# ESP32-H21 register map
Vendor: ESPRESSIF SYSTEMS (SHANGHAI) CO., LTD.; Series: ESP32 H-Series; File version: 1
CPU: RV32IMAC r0p0, little endian, no MPU, no FPU, 0 interrupt priority bits
Address unit: 32 bits
Registers are 32-bit, read-write, reset 0x0 unless marked. A register's access mark holds for its fields unless they carry their own. Offsets are from the block's base; [hi:lo] are bit positions; {n}, {i} and the like mark numbered series.

## LEDC — LED Control PWM (Pulse Width Modulation)
Base 0x60008000
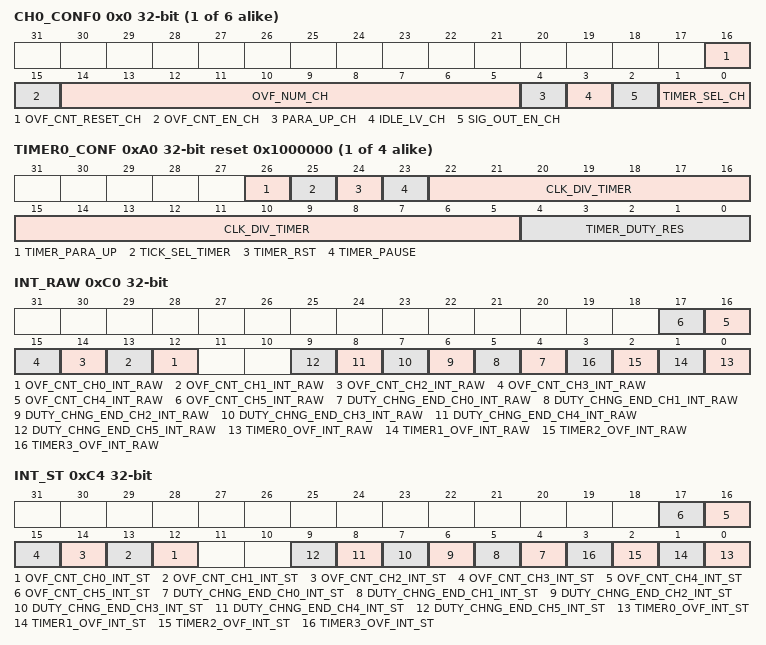
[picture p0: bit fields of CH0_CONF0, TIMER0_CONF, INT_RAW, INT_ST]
{0x0+0x14*i} CH{i}_CONF0 (i=0..5) access per field — Configuration register 0 for channel {i}
  [16] OVF_CNT_RESET_CH wo — Set this bit to reset the ovf_cnt of channel %s.
  [15] OVF_CNT_EN_CH rw — This bit is used to enable the ovf_cnt of channel %s.
  [14:5] OVF_NUM_CH rw — This register is used to configure the maximum times of overflow minus 1. The LEDC_OVF_CNT_CH%s_INT interrupt will be triggered when channel %s overflows for (LEDC_OVF_NUM_CH%s + 1) times.
  [4] PARA_UP_CH wo — This bit is used to update LEDC_HPOINT_CH%s, LEDC_DUTY_START_CH%s, LEDC_SIG_OUT_EN_CH%s, LEDC_TIMER_SEL_CH%s, LEDC_DUTY_NUM_CH%s, LEDC_DUTY_CYCLE_CH%s, LEDC_DUTY_SCALE_CH%s, LEDC_DUTY_INC_CH%s, and LEDC_OVF_CNT_EN_CH%s fields for channel %s, and will be automatically cleared by hardware.
  [3] IDLE_LV_CH rw — This bit is used to control the output value when channel %s is inactive (when LEDC_SIG_OUT_EN_CH%s is 0).
  [2] SIG_OUT_EN_CH rw — Set this bit to enable signal output on channel %s.
  [1:0] TIMER_SEL_CH rw — This field is used to select one of timers for channel %s. 0: select timer0, 1: select timer1, 2: select timer2, 3: select timer3
{0x4+0x14*i} CH{i}_HPOINT (i=0..5) — High point register for channel {i}
  [19:0] HPOINT_CH — The output value changes to high when the selected timers has reached the value specified by this register.
{0x8+0x14*i} CH{i}_DUTY (i=0..5) — Initial duty cycle for channel {i}
  [24:0] DUTY_CH — This register is used to change the output duty by controlling the Lpoint. The output value turns to low when the selected timers has reached the Lpoint.
{0xC+0x14*i} CH{i}_CONF1 (i=0..5) — Configuration register 1 for channel {i}
  [31] DUTY_START_CH — Other configured fields in LEDC_CH%s_CONF1_REG will start to take effect when this bit is set to 1.
{0x10+0x14*i} CH{i}_DUTY_R ro (i=0..2) — Current duty cycle for channel $n
  [24:0] DUTY_CH{i}_R — This register stores the current duty of output signal on channel {i}.
0x4C CH3_DUTY_R ro — Initial duty cycle for channel $n
  [24:0] DUTY_CH3_R — This register stores the current duty of output signal on channel 3.
0x60 CH4_DUTY_R ro — Current duty cycle for channel $n
  [24:0] DUTY_CH4_R — This register stores the current duty of output signal on channel 4.
0x74 CH5_DUTY_R ro — Current duty cycle for channel $n
  [24:0] DUTY_CH5_R — This register stores the current duty of output signal on channel 5.
{0xA0+8i} TIMER{i}_CONF (i=0..3) access per field reset 0x1000000 — Timer {i} configuration
  [26] TIMER_PARA_UP wo — Set this bit to update LEDC_CLK_DIV_TIMER%s and LEDC_TIMER%s_DUTY_RES.
  [25] TICK_SEL_TIMER rw — This bit is used to select clock for timer %s. When this bit is set to 1 LEDC_APB_CLK_SEL[1:0] should be 1, otherwise the timer clock may be not accurate. 1'h0: SLOW_CLK 1'h1: REF_TICK
  [24] TIMER_RST rw — This bit is used to reset timer %s. The counter will show 0 after reset.
  [23] TIMER_PAUSE rw — This bit is used to suspend the counter in timer %s.
  [22:5] CLK_DIV_TIMER rw — This register is used to configure the divisor for the divider in timer %s. The least significant eight bits represent the fractional part.
  [4:0] TIMER_DUTY_RES rw — This register is used to control the range of the counter in timer %s.
{0xA4+8i} TIMER{i}_VALUE (i=0..3) ro — Timer {i} current counter value
  [19:0] TIMER_CNT — This register stores the current counter value of timer %s.
0xC0 INT_RAW — Raw interrupt status
  [n+12] OVF_CNT_CH{n}_INT_RAW (n=0..5) — Interrupt raw bit for channel {n}. Triggered when the ovf_cnt has reached the value specified by LEDC_OVF_NUM_CH{n}.
  [n+4] DUTY_CHNG_END_CH{n}_INT_RAW (n=0..5) — Interrupt raw bit for channel {n}. Triggered when the gradual change of duty has finished.
  [n] TIMER{n}_OVF_INT_RAW (n=0..3) — Triggered when the timer{n} has reached its maximum counter value.
0xC4 INT_ST ro — Masked interrupt status
  [n+12] OVF_CNT_CH{n}_INT_ST (n=0..5) — This is the masked interrupt status bit for the LEDC_OVF_CNT_CH{n}_INT interrupt when LEDC_OVF_CNT_CH{n}_INT_ENA is set to 1.
  [n+4] DUTY_CHNG_END_CH{n}_INT_ST (n=0..5) — This is the masked interrupt status bit for the LEDC_DUTY_CHNG_END_CH{n}_INT interrupt when LEDC_DUTY_CHNG_END_CH{n}_INT_ENA is set to 1.
  [n] TIMER{n}_OVF_INT_ST (n=0..3) — This is the masked interrupt status bit for the LEDC_TIMER{n}_OVF_INT interrupt when LEDC_TIMER{n}_OVF_INT_ENA is set to 1.
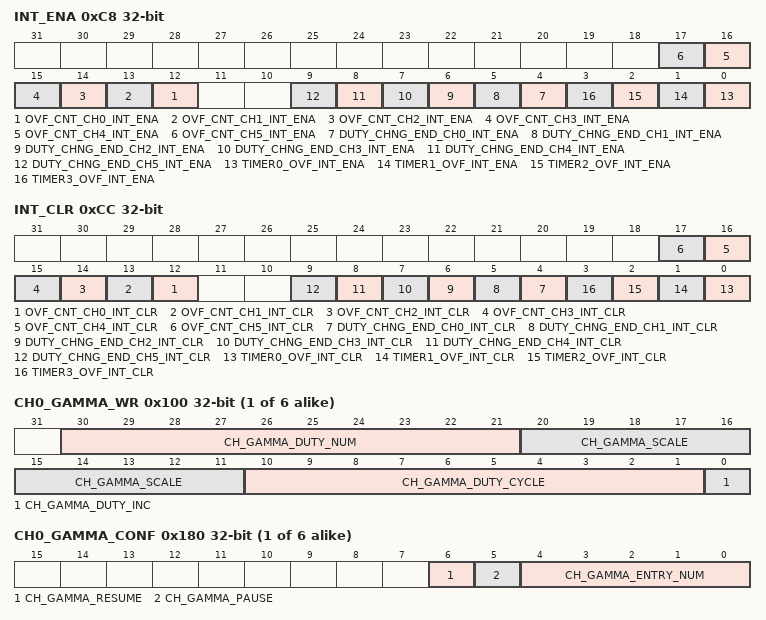
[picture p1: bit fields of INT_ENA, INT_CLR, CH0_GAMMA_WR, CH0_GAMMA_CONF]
0xC8 INT_ENA — Interrupt enable bits
  [n+12] OVF_CNT_CH{n}_INT_ENA (n=0..5) — The interrupt enable bit for the LEDC_OVF_CNT_CH{n}_INT interrupt.
  [n+4] DUTY_CHNG_END_CH{n}_INT_ENA (n=0..5) — The interrupt enable bit for the LEDC_DUTY_CHNG_END_CH{n}_INT interrupt.
  [n] TIMER{n}_OVF_INT_ENA (n=0..3) — The interrupt enable bit for the LEDC_TIMER{n}_OVF_INT interrupt.
0xCC INT_CLR wo — Interrupt clear bits
  [n+12] OVF_CNT_CH{n}_INT_CLR (n=0..5) — Set this bit to clear the LEDC_OVF_CNT_CH{n}_INT interrupt.
  [n+4] DUTY_CHNG_END_CH{n}_INT_CLR (n=0..5) — Set this bit to clear the LEDC_DUTY_CHNG_END_CH{n}_INT interrupt.
  [n] TIMER{n}_OVF_INT_CLR (n=0..3) — Set this bit to clear the LEDC_TIMER{n}_OVF_INT interrupt.
{0x100+0x10*i} CH{i}_GAMMA_WR (i=0..5) — Ledc ch{i} gamma ram write register.
  [30:21] CH_GAMMA_DUTY_NUM — Ledc ch%s gamma duty num of current ram write address.This register is used to control the number of times the duty cycle will be changed.
  [20:11] CH_GAMMA_SCALE — Ledc ch%s gamma scale of current ram write address.This register is used to configure the changing step scale of duty on channel %s.
  [10:1] CH_GAMMA_DUTY_CYCLE — Ledc ch%s gamma duty cycle of current ram write address.The duty will change every LEDC_CH%s_GAMMA_DUTY_CYCLE on channel %s.
  [0] CH_GAMMA_DUTY_INC — Ledc ch%s gamma duty inc of current ram write address.This register is used to increase or decrease the duty of output signal on channel %s. 1: Increase 0: Decrease.
{0x104+0x10*i} CH{i}_GAMMA_WR_ADDR (i=0..5) — Ledc ch{i} gamma ram write address register.
  [3:0] CH_GAMMA_WR_ADDR — Ledc ch%s gamma ram write address.
{0x108+0x10*i} CH{i}_GAMMA_RD_ADDR (i=0..5) — Ledc ch{i} gamma ram read address register.
  [3:0] CH_GAMMA_RD_ADDR — Ledc ch%s gamma ram read address.
{0x10C+0x10*i} CH{i}_GAMMA_RD_DATA (i=0..5) ro — Ledc ch{i} gamma ram read data register.
  [30:0] CH_GAMMA_RD_DATA — Ledc ch%s gamma ram read data.
{0x180+4i} CH{i}_GAMMA_CONF (i=0..5) access per field — Ledc ch{i} gamma config register.
  [6] CH_GAMMA_RESUME wo — Ledc ch%s gamma resume, write 1 to resume.
  [5] CH_GAMMA_PAUSE wo — Ledc ch%s gamma pause, write 1 to pause.
  [4:0] CH_GAMMA_ENTRY_NUM rw — Ledc ch%s gamma entry num.
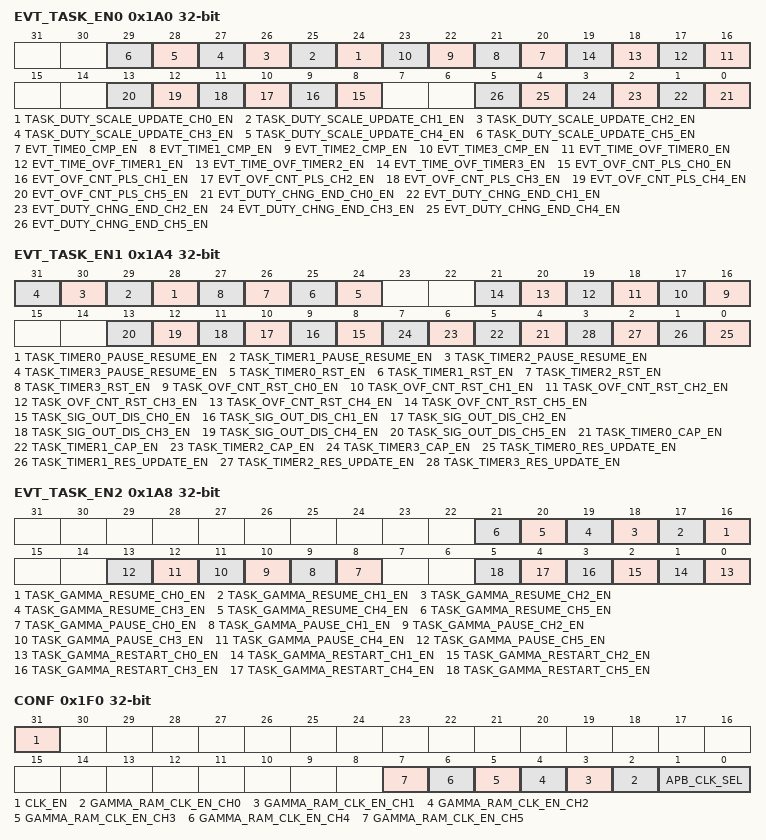
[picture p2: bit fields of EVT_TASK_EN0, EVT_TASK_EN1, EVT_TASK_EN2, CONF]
0x1A0 EVT_TASK_EN0 — Ledc event task enable bit register0.
  [n+24] TASK_DUTY_SCALE_UPDATE_CH{n}_EN (n=0..5) — Ledc ch{n} duty scale update task enable register, write 1 to enable this task.
  [n+20] EVT_TIME{n}_CMP_EN (n=0..3) — Ledc timer{n} compare event enable register, write 1 to enable this event.
  [n+16] EVT_TIME_OVF_TIMER{n}_EN (n=0..3) — Ledc timer{n} overflow event enable register, write 1 to enable this event.
  [n+8] EVT_OVF_CNT_PLS_CH{n}_EN (n=0..5) — Ledc ch{n} overflow count pulse event enable register, write 1 to enable this event.
  [n] EVT_DUTY_CHNG_END_CH{n}_EN (n=0..5) — Ledc ch{n} duty change end event enable register, write 1 to enable this event.
0x1A4 EVT_TASK_EN1 — Ledc event task enable bit register1.
  [n+28] TASK_TIMER{n}_PAUSE_RESUME_EN (n=0..3) — Ledc timer{n} pause resume task enable register, write 1 to enable this task.
  [n+24] TASK_TIMER{n}_RST_EN (n=0..3) — Ledc timer{n} reset task enable register, write 1 to enable this task.
  [n+16] TASK_OVF_CNT_RST_CH{n}_EN (n=0..5) — Ledc ch{n} overflow count reset task enable register, write 1 to enable this task.
  [n+8] TASK_SIG_OUT_DIS_CH{n}_EN (n=0..5) — Ledc ch{n} signal out disable task enable register, write 1 to enable this task.
  [n+4] TASK_TIMER{n}_CAP_EN (n=0..3) — Ledc timer{n} capture task enable register, write 1 to enable this task.
  [n] TASK_TIMER{n}_RES_UPDATE_EN (n=0..3) — Ledc timer{n} res update task enable register, write 1 to enable this task.
0x1A8 EVT_TASK_EN2 — Ledc event task enable bit register2.
  [n+16] TASK_GAMMA_RESUME_CH{n}_EN (n=0..5) — Ledc ch{n} gamma resume task enable register, write 1 to enable this task.
  [n+8] TASK_GAMMA_PAUSE_CH{n}_EN (n=0..5) — Ledc ch{n} gamma pause task enable register, write 1 to enable this task.
  [n] TASK_GAMMA_RESTART_CH{n}_EN (n=0..5) — Ledc ch{n} gamma restart task enable register, write 1 to enable this task.
{0x1B0+4i} TIMER{i}_CMP (i=0..3) — Ledc timer{i} compare value register.
  [19:0] TIMER_CMP — This register stores ledc timer%s compare value.
{0x1C0+4i} TIMER{i}_CNT_CAP (i=0..3) ro — Ledc timer{i} count value capture register.
  [19:0] TIMER_CNT_CAP — This register stores ledc timer%s count value.
0x1F0 CONF — Global ledc configuration register
  [31] CLK_EN — This bit is used to control clock. 1'b1: Force clock on for register. 1'h0: Support clock only when application writes registers.
  [n+2] GAMMA_RAM_CLK_EN_CH{n} (n=0..5) — This bit is used to control clock. 1'b1: Force clock on for gamma ram. 1'h0: Support clock only when application writes or read gamma ram.
  [1:0] APB_CLK_SEL — This bit is used to select clock source for the 4 timers . 2'd1: APB_CLK 2'd2: RTC8M_CLK 2'd3: XTAL_CLK
0x1FC DATE reset 0x2111150 — Version control register
  [27:0] LEDC_DATE — This is the version control register.
